AUTOSAR XML (schema 314)
package /ComponentType
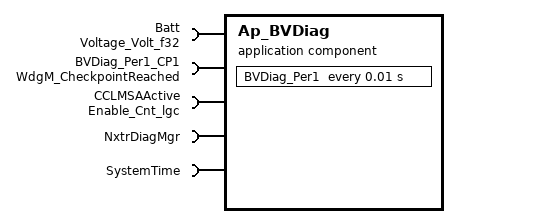
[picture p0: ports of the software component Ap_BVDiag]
  application software component type Ap_BVDiag
    5 x require port:
      Batt: unqueued-receiver-com-spec{data-element=Volt_f32, init-value=D_ZERO_ULS_F32}, required-interface=Voltage_Volt_f32
      BVDiag_Per1_CP1: client-com-spec=CheckpointReached, required-interface=WdgM_CheckpointReached
      CCLMSAActive: unqueued-receiver-com-spec{data-element=Cnt_lgc, init-value=D_FALSE_CNT_LGC}, required-interface=Enable_Cnt_lgc
      NxtrDiagMgr: required-com-specs=[GetNTCActive, GetNTCFailed, GetNTCStatus, SetNTCStatus], required-interface=NxtrDiagMgr
      SystemTime: required-interface=SystemTime
        required-com-specs:
          DtrmnElapsedTime_mS_u16
          DtrmnElapsedTime_mS_u32
          DtrmnElapsedTime_uS_u16
          DtrmnElapsedTime_uS_u32
          GetSystemTime_mS_u32
          GetSystemTime_uS_u32
  internal behavior Ap_BVDiag_InternalBehavior: component=Ap_BVDiag
    timing event TMT_BVDiag_Per1: start-on-event=BVDiag_Per1, period=0.01
    port-api-options:
      enable-take-address=false, indirect-api=false, port=Batt
      enable-take-address=false, indirect-api=false, port=BVDiag_Per1_CP1
      enable-take-address=false, indirect-api=false, port=CCLMSAActive
      enable-take-address=false, indirect-api=false, port=NxtrDiagMgr
      enable-take-address=false, indirect-api=false, port=SystemTime
    runnable BVDiag_Per1
      data read access READ_Batt_Volt_f32: data-element=Batt.Volt_f32
      data read access READ_CCLMSAActive_Cnt_lgc: data-element=CCLMSAActive.Cnt_lgc
      4 x sync call, all with timeout=0:
        SC_BVDiag_Per1_CP1_CheckpointReached: operation=BVDiag_Per1_CP1.CheckpointReached
        SC_NxtrDiagMgr_SetNTCStatus: operation=NxtrDiagMgr.SetNTCStatus
        SC_SystemTime_DtrmnElapsedTime_mS_u16: operation=SystemTime.DtrmnElapsedTime_mS_u16
        SC_SystemTime_GetSystemTime_mS_u32: operation=SystemTime.GetSystemTime_mS_u32
  swc implementation Ap_BVDiag_Implementation: behavior=Ap_BVDiag_InternalBehavior
    code-descriptors:
      code Code: type=SRC
